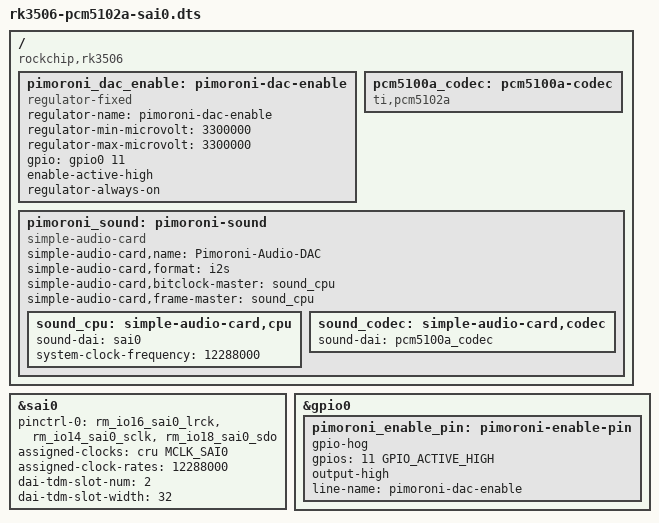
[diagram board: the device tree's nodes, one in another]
// SPDX-License-Identifier: MIT
/*
 * Device Tree Overlay for Pimoroni Audio DAC SHIM (PCM5100A) on SAI0
 * Copyright (c) 2024 Christopher Nadler
 *
 * Pimoroni Audio DAC SHIM Pin connections (using rm_io pins):
 * rm_io16 (SAI0_LRCK) -> PCM5100A LRCK (Left/Right Clock / WS)
 * rm_io14 (SAI0_SCLK) -> PCM5100A BCK (Bit Clock)
 * rm_io18 (SAI0_SDO)  -> PCM5100A DIN (Data Input)
 * rm_io11 (GPIO)      -> PCM5100A Enable (Active High)
 *
 * Note: Pimoroni Audio DAC SHIM doesn't require MCLK - the PCM5100A
 * generates the system clock internally from BCK.
 *
 * Pimoroni Audio DAC SHIM additional connections:
 * VDD  -> 3.3V (via GPIO header)
 * GND  -> GND (via GPIO header)
 *
 * Overlay usage:
 * 1. Compile: dtc -@ -I dts -O dtb -o rk3506-pimoroni-audio-dac-shim.dtbo rk3506-pcm5102a-sai0.dts
 * 2. Copy to /boot/overlays/
 * 3. Add to config: overlays=rk3506-pimoroni-audio-dac-shim
 */

/dts-v1/;
/plugin/;

#include <dt-bindings/clock/rockchip,rk3506-cru.h>
#include <dt-bindings/gpio/gpio.h>

/ {
	compatible = "rockchip,rk3506";

	fragment@0 {
		target-path = "/";
		__overlay__ {
			pimoroni_dac_enable: pimoroni-dac-enable {
				compatible = "regulator-fixed";
				regulator-name = "pimoroni-dac-enable";
				regulator-min-microvolt = <3300000>;
				regulator-max-microvolt = <3300000>;
				gpio = <&gpio0 11 GPIO_ACTIVE_HIGH>; /* rm_io11 = GPIO0_B3 */
				enable-active-high;
				regulator-always-on;
			};

			pcm5100a_codec: pcm5100a-codec {
				#sound-dai-cells = <0>;
				compatible = "ti,pcm5102a"; /* PCM5100A is compatible */
				status = "okay";
			};

			pimoroni_sound: pimoroni-sound {
				compatible = "simple-audio-card";
				simple-audio-card,name = "Pimoroni-Audio-DAC";
				simple-audio-card,format = "i2s";
				simple-audio-card,bitclock-master = <&sound_cpu>;
				simple-audio-card,frame-master = <&sound_cpu>;
				status = "okay";

				sound_cpu: simple-audio-card,cpu {
					sound-dai = <&sai0>;
					system-clock-frequency = <12288000>;
				};

				sound_codec: simple-audio-card,codec {
					sound-dai = <&pcm5100a_codec>;
				};
			};
		};
	};

	fragment@1 {
		target = <&sai0>;
		__overlay__ {
			#sound-dai-cells = <0>;
			status = "okay";
			pinctrl-names = "default";
			pinctrl-0 = <&rm_io16_sai0_lrck
				     &rm_io14_sai0_sclk
				     &rm_io18_sai0_sdo>;
			assigned-clocks = <&cru MCLK_SAI0>;
			assigned-clock-rates = <12288000>;
			dai-tdm-slot-num = <2>;
			dai-tdm-slot-width = <32>;
		};
	};

	fragment@2 {
		target = <&gpio0>;
		__overlay__ {
			pimoroni_enable_pin: pimoroni-enable-pin {
				gpio-hog;
				gpios = <11 GPIO_ACTIVE_HIGH>; /* GPIO0_B3 = rm_io11 */
				output-high;
				line-name = "pimoroni-dac-enable";
			};
		};
	};
};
